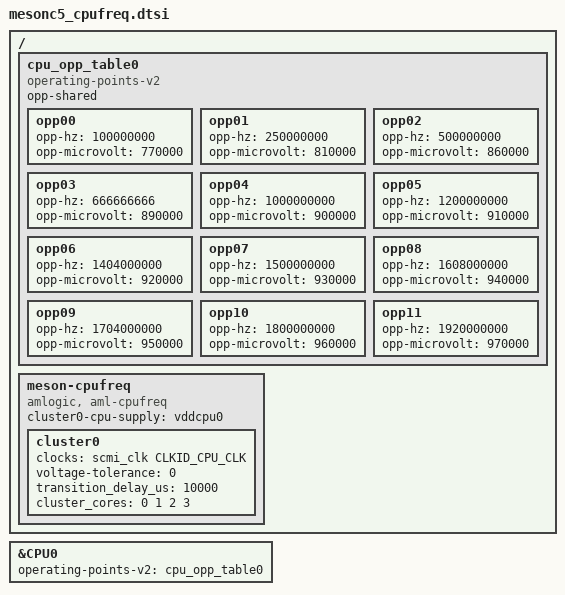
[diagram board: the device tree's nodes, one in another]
// SPDX-License-Identifier: (GPL-2.0+ OR MIT)
/*
 * Copyright (c) 2019 Amlogic, Inc. All rights reserved.
 */

/ {
	cpu_opp_table0: cpu_opp_table0 {
		compatible = "operating-points-v2";
		opp-shared;

		opp00 {
			opp-hz = /bits/ 64 <100000000>;
			opp-microvolt = <770000>;
		};
		opp01 {
			opp-hz = /bits/ 64 <250000000>;
			opp-microvolt = <810000>;
		};
		opp02 {
			opp-hz = /bits/ 64 <500000000>;
			opp-microvolt = <860000>;
		};
		opp03 {
			opp-hz = /bits/ 64 <666666666>;
			opp-microvolt = <890000>;
		};
		opp04 {
			opp-hz = /bits/ 64 <1000000000>;
			opp-microvolt = <900000>;
		};
		opp05 {
			opp-hz = /bits/ 64 <1200000000>;
			opp-microvolt = <910000>;
		};
		opp06 {
			opp-hz = /bits/ 64 <1404000000>;
			opp-microvolt = <920000>;
		};
		opp07 {
			opp-hz = /bits/ 64 <1500000000>;
			opp-microvolt = <930000>;
		};
		opp08 {
			opp-hz = /bits/ 64 <1608000000>;
			opp-microvolt = <940000>;
		};
		opp09 {
			opp-hz = /bits/ 64 <1704000000>;
			opp-microvolt = <950000>;
		};
		opp10 {
			opp-hz = /bits/ 64 <1800000000>;
			opp-microvolt = <960000>;
		};
		opp11 {
			opp-hz = /bits/ 64 <1920000000>;
			opp-microvolt = <970000>;
		};
	};

	meson-cpufreq {
		compatible = "amlogic, aml-cpufreq";
		status = "okay";

		cluster0-cpu-supply = <&vddcpu0>;

		cluster0 {
			clocks = <&scmi_clk CLKID_CPU_CLK>;
			clock-names = "cpuclk";
			voltage-tolerance = <0>;
			transition_delay_us = <10000>;
			//skip_volt_scaling;
			cluster_cores = <0 1 2 3>;
			//pdvfs_enabled;
		};
	};
};/* end of / */

&CPU0 {
	operating-points-v2 = <&cpu_opp_table0>;
};
